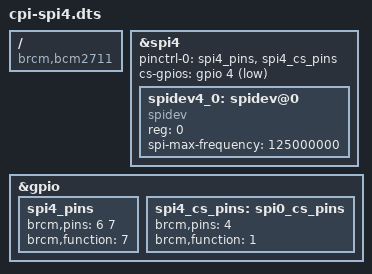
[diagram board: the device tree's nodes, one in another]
/dts-v1/;
/plugin/;

/{
	compatible = "brcm,bcm2711";

	fragment@1 {
		target = <&spi4>;
		__overlay__ {
			pinctrl-names = "default";
			pinctrl-0 = <&spi4_pins &spi4_cs_pins>;
			cs-gpios = <&gpio 4 1>;
			status = "okay";

			spidev4_0: spidev@0 {
				compatible = "spidev";
				reg = <0>;      /* CE0 */
				#address-cells = <1>;
				#size-cells = <0>;
				spi-max-frequency = <125000000>;
				status = "okay";
			};
		};
	};

	fragment@2 {
		target = <&gpio>;
		__overlay__ {

			spi4_pins: spi4_pins {
				brcm,pins = <6 7>;
				brcm,function = <7>;
			};

			spi4_cs_pins: spi0_cs_pins {
				brcm,pins = <4>;
				brcm,function = <1>;
			};
		};
	};	
};
